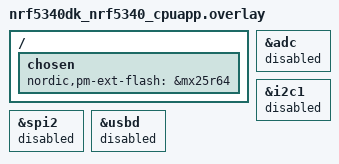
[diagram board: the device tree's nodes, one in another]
/*
 * Copyright (c) 2024 Nordic Semiconductor ASA
 *
 * SPDX-License-Identifier: LicenseRef-Nordic-5-Clause
 */

/ {
	chosen {
		nordic,pm-ext-flash = &mx25r64;
	};
};

/* Disable unused peripherals to reduce power consumption */
&adc {
	status = "disabled";
};
&i2c1 {
	status = "disabled";
};
&spi2 {
	status = "disabled";
};
&usbd {
	status = "disabled";
};
